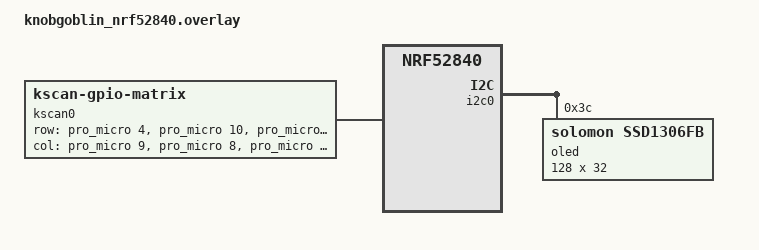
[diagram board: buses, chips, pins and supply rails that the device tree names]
#include "knobgoblin_nrf52840.dtsi"

/ {
    chosen {
        zmk,kscan = &kscan0;
        zephyr,display = &oled;
    };

    kscan0: kscan0 {
        compatible = "zmk,kscan-gpio-matrix";
        diode-direction = "col2row";
        wakeup-source;

        row-gpios
            = <&pro_micro 4 (GPIO_ACTIVE_HIGH | GPIO_PULL_DOWN)>
            , <&pro_micro 10 (GPIO_ACTIVE_HIGH | GPIO_PULL_DOWN)>
            , <&pro_micro 16 (GPIO_ACTIVE_HIGH | GPIO_PULL_DOWN)>
            , <&pro_micro 14 (GPIO_ACTIVE_HIGH | GPIO_PULL_DOWN)>
            , <&pro_micro 15 (GPIO_ACTIVE_HIGH | GPIO_PULL_DOWN)>
            ;

        col-gpios
            = <&pro_micro 9 GPIO_ACTIVE_HIGH>
            , <&pro_micro 8 GPIO_ACTIVE_HIGH>
            , <&pro_micro 7 GPIO_ACTIVE_HIGH>
            , <&pro_micro 6 GPIO_ACTIVE_HIGH>
            , <&pro_micro 5 GPIO_ACTIVE_HIGH>
            ;
    };
};

// Define the I2C bus and the display configuration
&i2c0 {
    status = "okay";

    oled: ssd1306@3c {
        compatible = "solomon,ssd1306fb";
        reg = <0x3c>;
        width = <128>;
        height = <32>;
        segment-offset = <0>;
        page-offset = <0>;
        display-offset = <0>;
        multiplex-ratio = <31>;
        segment-remap;
        com-invdir;
        com-sequential;
        inversion-on;
        prechargep = <0x22>;
    };
};

&physical_layout_knobgoblin_nrf52840 {
    kscan = <&kscan0>;
};

